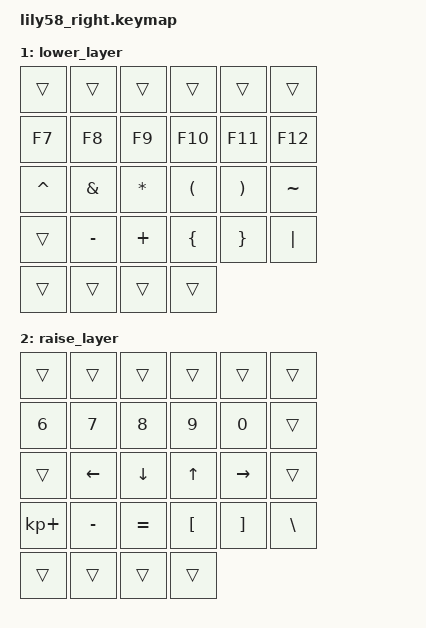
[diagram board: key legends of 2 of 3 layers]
/*
 * Copyright (c) 2020 The ZMK Contributors
 *
 * SPDX-License-Identifier: MIT
 */

#include <behaviors.dtsi>
#include <dt-bindings/zmk/keys.h>
#include <dt-bindings/zmk/bt.h>
#include <dt-bindings/zmk/ext_power.h>

/ {
    keymap {
        compatible = "zmk,keymap";

        default_layer {
// ------------------------------------------------------------------------------------------------------------
// |  ESC  |  1  |  2  |  3   |  4   |  5   |                   |  6   |  7    |  8    |  9   |   0   |   `   |
// |  TAB  |  Q  |  W  |  E   |  R   |  T   |                   |  Y   |  U    |  I    |  O   |   P   |   -   |
// |  CTRL |  A  |  S  |  D   |  F   |  G   |                   |  H   |  J    |  K    |  L   |   ;   |   '   |
// | SHIFT |  Z  |  X  |  C   |  V   |  B   |   "["  |  |  "]"  |  N   |  M    |  ,    |  .   |   /   | SHIFT |
//                     | ALT  | GUI  | LOWER|  SPACE |  | ENTER | RAISE| BSPC  | GUI   |
            bindings = <
&kp N6 &kp N7   &kp N8    &kp N9  &kp N0   &kp GRAVE
&kp Y  &kp U    &kp I     &kp O   &kp P    &kp MINUS
&kp H  &kp J    &kp K     &kp L   &kp SEMI &kp SQT
&kp RBKT &kp N  &kp M    &kp COMMA &kp DOT &kp FSLH &kp RSHFT
&kp RET  &mo 2  &kp BSPC &kp RGUI
            >;

            sensor-bindings = <&inc_dec_kp C_VOL_UP C_VOL_DN>;
        };

        lower_layer {
// ------------------------------------------------------------------------------------------------------------
// | BTCLR | BT1 | BT2 |  BT3 |  BT4 |  BT5 |                   |      |       |       |      |       |       |
// |  F1   |  F2 |  F3 |  F4  |  F5  |  F6  |                   |  F7  |  F8   |  F9   |  F10 |  F11  |  F12  |
// |   `   |  !  |  @  |  #   |  $   |  %   |                   |  ^   |  &    |  *    |  (   |   )   |   ~   |
// |       |     |     |      |      |      |        |  |       |      |  _    |  +    |  {   |   }   |  "|"  |
//                     |      |      |      |        |  |       |      |       |       |
            bindings = <
&trans    &trans    &trans    &trans    &trans    &trans
&kp F7    &kp F8    &kp F9    &kp F10   &kp F11   &kp F12
&kp CARET &kp AMPS  &kp ASTRK &kp LPAR  &kp RPAR  &kp TILDE
&trans    &kp MINUS &kp PLUS  &kp LBRC  &kp RBRC  &kp PIPE
&trans    &trans    &trans    &trans
            >;

            sensor-bindings = <&inc_dec_kp C_VOL_UP C_VOL_DN>;
        };

        raise_layer {
// ------------------------------------------------------------------------------------------------------------
// |       |     |     |      |      |      |                   |      |       |       |      |       |       |
// |   `   |  1  |  2  |  3   |  4   |  5   |                   |  6   |   7   |   8   |  9   |   0   |       |
// |   F1  |  F2 |  F3 |  F4  |  F5  |  F6  |                   |      |   <-  |   v   |  ^   |  ->   |       |
// |   F7  |  F8 |  F9 |  F10 |  F11 |  F12 |        |  |       |  +   |   -   |   =   |  [   |   ]   |   \   |
//                     |      |      |      |        |  |       |      |       |       |
            bindings = <
&trans      &trans    &trans    &trans   &trans    &trans
&kp N6      &kp N7    &kp N8    &kp N9   &kp N0    &trans
&trans      &kp LEFT  &kp DOWN  &kp UP   &kp RIGHT &trans
&kp KP_PLUS &kp MINUS &kp EQUAL &kp LBKT &kp RBKT  &kp BSLH
&trans    &trans      &trans    &trans
            >;

            sensor-bindings = <&inc_dec_kp C_VOL_UP C_VOL_DN>;
        };
    };
};
&kscan0 {
    col-gpios
        = <&pro_micro 10 GPIO_ACTIVE_HIGH>
        , <&pro_micro 16 GPIO_ACTIVE_HIGH>
        , <&pro_micro 14 GPIO_ACTIVE_HIGH>
        , <&pro_micro 21 GPIO_ACTIVE_HIGH>
        , <&pro_micro 18 GPIO_ACTIVE_HIGH>
        , <&pro_micro 19 GPIO_ACTIVE_HIGH>
        ;
};
